# max32657 register map
Vendor: Maxim-Integrated; Series: ARMCM33; File version: 1.0
CPU: CM4 r2p1, little endian, MPU, FPU, 3 interrupt priority bits
Registers are 32-bit, read-write, reset 0x0 unless marked. A register's access mark holds for its fields unless they carry their own. Offsets are from the block's base; [hi:lo] are bit positions.

## SIR — System Initialization Registers.
Base 0x50000400
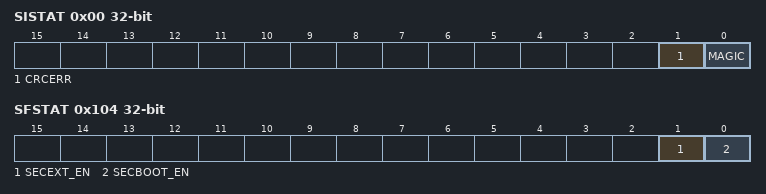
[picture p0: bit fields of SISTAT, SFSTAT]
0x00 SISTAT ro — System Initialization Status Register.
  [1] CRCERR — CRC Error Status. This bit is set by the system initialization block following power-up.
    on read: 0=noError (No CRC errors occurred during the read of the OTP memory block.); 1=error (A CRC error occurred while reading the OTP. The address of the failure location in the OTP memory is stored in the ERRADDR register.)
  [0] MAGIC — Magic Word Validation. This bit is set by the system initialization block following power-up.
    on read: 0=magicNotSet (Magic word was not set (OTP has not been initialized properly).); 1=magicSet (Magic word was set (OTP contains valid settings).)
0x04 ADDR ro — Read-only field set by the SIB block if a CRC error occurs during the read of the OTP memory. Contains the failing address in OTP memory (when CRCERR equals 1).
  [31:0] ERRADDR
0x1C BTLELDO_BB ro — BTLE LDO TRIM BB Register.
  [4:0] TRIM — Target 0.9V. VDDA BB Voltage Trim.
0x2C BTLELDO_RF ro — BTLE LDO TRIM RF Register.
  [4:0] TRIM — Target 0.9V. VDDA RF Voltage Trim.
0x104 SFSTAT ro — Security function status register.
  [1] SECEXT_EN — M33 SecExt Function Enable.
  [0] SECBOOT_EN — Security Boot.

## TRIMSIR — Trim System Initilazation Registers.
Base 0x50005400
0x3C RTCX1 — RTC X1 Capacitor Setting.
  [4:0] CAP — RTC X1 Load Capacitor Setting.
0x44 RTCX2 — RTC X2 Capacitor Setting.
  [4:0] CAP — RTC X2 Load Capacitor Setting.

## TRNG — Random Number Generator.
Base 0x5004D000
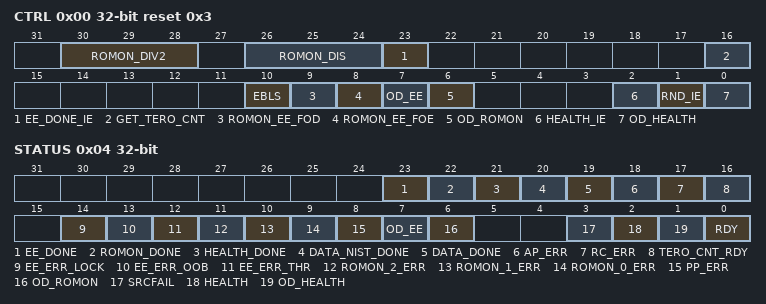
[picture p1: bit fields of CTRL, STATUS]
0x00 CTRL reset 0x3 — TRNG Control Register.
  [30:28] ROMON_DIV2 — Divide ring by 2.
    0=RO_0 (Ring Oscillator 0.); 1=RO_1 (Ring Oscillator 1.); 2=RO_2 (Ring Oscillator 2.)
  [26:24] ROMON_DIS — Ring Oscillator Disable.
    1=RO_0 (Ring Oscillator 0.); 2=RO_1 (Ring Oscillator 1.); 4=RO_2 (Ring Oscillator 2.)
  [23] EE_DONE_IE — Entropy Estimator Done Interrupt Enable.
  [16] GET_TERO_CNT — Get Tero Count.
  [10] EBLS — Entropy Bit Load Select.
  [9] ROMON_EE_FOD — Ring Oscillator Monitors and Entropy Estimator Freeze on Done.
  [8] ROMON_EE_FOE — Ring Oscillator Monitors and Entropy Estimator Freeze on Error.
  [7] OD_EE — Start entropy estimator on demand test.
  [6] OD_ROMON — Start ring oscillator monitor on demand test.
  [2] HEALTH_IE — Enable IRQ generation when a health test fails.
  [1] RND_IE — To enable IRQ generation when a new 32-bit Random number is ready.
    0=disable; 1=enable
  [0] OD_HEALTH — Start On-Demand health test.
0x04 STATUS — Data. The content of this register is valid only when RNG_IS = 1. When TRNG is disabled, read returns 0x0000 0000.
  [23] EE_DONE — Entropy Estimator Test Done.
  [22] ROMON_DONE — Ring Oscillator Monitor Test Done.
  [21] HEALTH_DONE — Health Test Done.
  [20] DATA_NIST_DONE — Data NIST register has been loaded with at least 32 new entropy bits.
  [19] DATA_DONE — Data register has been loaded with at least 32 new entropy bits.
  [18] AP_ERR — Adaptive Proportion Error.
  [17] RC_ERR — Repetition Count Error.
  [16] TERO_CNT_RDY — TERO Count Ready.
  [14] EE_ERR_LOCK — Entropy Estimator Lock Error.
  [13] EE_ERR_OOB — Entropy Estimator Out of Bounds Error..
  [12] EE_ERR_THR — Entropy Estimator Threshold Error.
  [11] ROMON_2_ERR — Ring Oscillator 2 Monitor Error.
  [10] ROMON_1_ERR — Ring Oscillator 1 Monitor Error.
  [9] ROMON_0_ERR — Ring Oscillator 0 Monitor Error.
  [8] PP_ERR — Post process error.
  [7] OD_EE — On demand entropy estimator status.
  [6] OD_ROMON — On demand ring oscillator test status.
  [3] SRCFAIL — Entropy source has failed.
  [2] HEALTH — Health test status.
  [1] OD_HEALTH — On-Demand health test status.
  [0] RDY — 32-bit random data is ready to read from TRNG_DATA register. Reading TRNG_DATA when RND_RDY=0 will return all 0's. IRQ is generated when RND_RDY=1 if TRNG_CN.RND_IRQ_EN=1.
    0=Busy (TRNG Busy); 1=Ready (32 bit random data is ready)
0x08 DATA ro — Data. The content of this register is valid only when RNG_IS = 1. When TRNG is disabled, read returns 0x0000 0000.
  [31:0] DATA — Data. The content of this register is valid only when RNG_IS =1. When TNRG is disabled, read returns 0x0000 0000.
0x38 DATA_NIST
  [31:0] DATA — Ring Oscillator 1 Monitor Last Ring Oscillator Count.

## WUT — 32-bit reloadable timer that can be used for timing and wakeup.
Base 0x50006400
0x00 CNT reset 0x1 — Count. This register stores the current timer count.
  [31:0] COUNT — Timer Count Value.
0x04 CMP reset 0xFFFF — Compare. This register stores the compare value, which is used to set the maximum count value to initiate a reload of the timer to 0x0001.
  [31:0] COMPARE — Timer Compare Value.
0x0C INTFL write-1-clears — Clear Interrupt. Writing a value (0 or 1) to a bit in this register clears the associated interrupt.
  [0] CLR — Clear Interrupt.
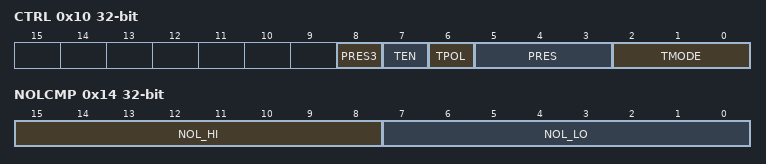
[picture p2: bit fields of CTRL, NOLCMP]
0x10 CTRL — Timer Control Register.
  [8] PRES3 — MSB of prescaler value.
  [7] TEN — Timer Enable.
    0=dis (Disable.); 1=en (Enable.)
  [6] TPOL — Timer input/output polarity bit.
    0=Active High; 1=Active Low
  [5:3] PRES — Prescaler. Set the Timer's prescaler value. The prescaler divides the PCLK input to the timer and sets the Timer's Count Clock, F_CNT_CLK = PCLK(HZ)/prescaler. The Timer's prescaler setting is a 4-bit value with pres3:pres[2:0].
    0=div1 (Divide by 1.); 1=div2 (Divide by 2.); 2=div4 (Divide by 4.); 3=div8 (Divide by 8.); 4=div16 (Divide by 16.); 5=div32 (Divide by 32.); 6=div64 (Divide by 64.); 7=div128 (Divide by 128.)
  [2:0] TMODE — Timer Mode.
    0=One Shot Mode; 1=Continuous Mode; 2=Counter Mode; 4=Capture Mode; 5=Compare Mode; 6=Gated Mode; 7=Capture/Compare Mode
0x14 NOLCMP — Timer Non-Overlapping Compare Register.
  [15:8] NOL_HI — Non-overlapping High Compare. The 8-bit timer count value of non-overlapping time between falling edge of PWM output 0A' and next rising edge of PWM output 0A.
  [7:0] NOL_LO — Non-overlapping Low Compare. The 8-bit timer count value of non-overlapping time between falling edge of PWM output 0A and next rising edge of PWM output 0A'.
0x18 PRESET
  [31:0] PRESET — Preset Value.
0x1C RELOAD
  [31:0] RELOAD — Rerload Value.
0x20 SNAPSHOT
  [31:0] SNAPSHOT — Snapshot Value.
